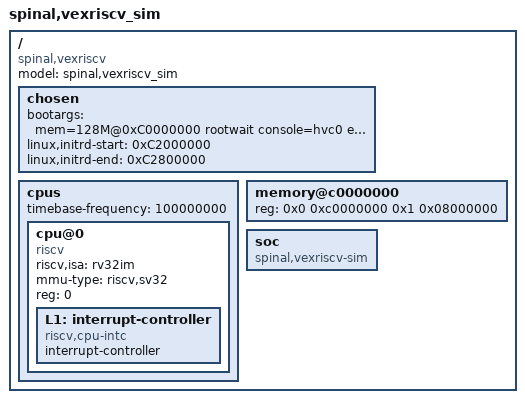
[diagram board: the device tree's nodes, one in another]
/dts-v1/;

/ {
	#address-cells = <0x2>;
	#size-cells = <0x2>;
	compatible = "spinal,vexriscv";
	model = "spinal,vexriscv_sim";


	chosen {
		bootargs = "mem=128M@0xC0000000 rootwait console=hvc0 earlycon=sbi root=/dev/ram0 init=/sbin/init";
		linux,initrd-start = <0xC2000000>;
		linux,initrd-end = <0xC2800000>; // max 8MB ramdisk image
	};

    cpus {
        #address-cells = <0x1>;
        #size-cells = <0x0>;
        timebase-frequency = <100000000>;
        cpu@0 {
            device_type = "cpu";
            compatible = "riscv";
            riscv,isa = "rv32im";
            mmu-type = "riscv,sv32";
            reg = <0>;
            status = "okay";
            L1: interrupt-controller {
                #interrupt-cells = <0x00000001>;
                interrupt-controller;
                compatible = "riscv,cpu-intc";
            };
        };
/*
        cpu@1 {
            device_type = "cpu";
            compatible = "riscv";
            riscv,isa = "rv32im";
            mmu-type = "riscv,sv32";
            reg = <1>;
            status = "okay";
            L2: interrupt-controller {
                #interrupt-cells = <0x00000001>;
                interrupt-controller;
                compatible = "riscv,cpu-intc";
            };
        };

        cpu@2 {
            device_type = "cpu";
            compatible = "riscv";
            riscv,isa = "rv32im";
            mmu-type = "riscv,sv32";
            reg = <2>;
            status = "okay";
            L3: interrupt-controller {
                #interrupt-cells = <0x00000001>;
                interrupt-controller;
                compatible = "riscv,cpu-intc";
            };
        };

        cpu@3 {
            device_type = "cpu";
            compatible = "riscv";
            riscv,isa = "rv32im";
            mmu-type = "riscv,sv32";
            reg = <3>;
            status = "okay";
            L4: interrupt-controller {
                #interrupt-cells = <0x00000001>;
                interrupt-controller;
                compatible = "riscv,cpu-intc";
            };
        };*/
	};

	memory@c0000000 {
		device_type = "memory";
		reg = <0x0 0xc0000000 0x1 0x08000000>;
	};

	soc {
		#address-cells = <0x2>;
		#size-cells = <0x2>;
		compatible = "spinal,vexriscv-sim";
		ranges;
	};
};
